# ESW3120 register map
Vendor: Shanghai Eastsoft Microelectronics Co.,Ltd.; Series: ARMCM3; File version: 1.2
CPU: CM3 r2p1, little endian, MPU, no FPU, 4 interrupt priority bits
Registers are 32-bit, read-write, reset 0x0 unless marked. A register's access mark holds for its fields unless they carry their own. Offsets are from the block's base; [hi:lo] are bit positions; {n}, {i} and the like mark numbered series.

## AFE
Base 0x400E0400
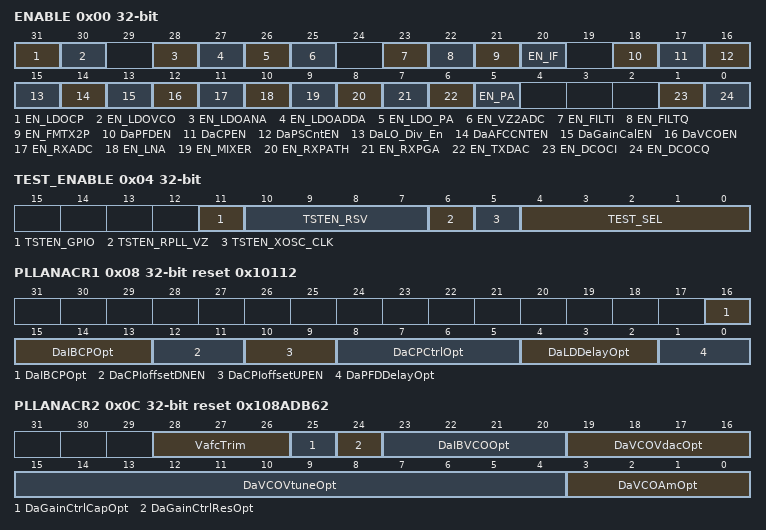
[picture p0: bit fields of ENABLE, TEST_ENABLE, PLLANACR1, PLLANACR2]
0x00 ENABLE
  [31] EN_LDOCP, [30] EN_LDOVCO, [28] EN_LDOANA, [27] EN_LDOADDA, [26] EN_LDO_PA, [25] EN_VZ2ADC, [23] EN_FILTI, [22] EN_FILTQ, [21] EN_FMTX2P, [20] EN_IF, [18] DaPFDEN, [17] DaCPEN, [16] DaPSCntEN, [15] DaLO_Div_En, [14] DaAFCCNTEN, [13] DaGainCalEN, [12] DaVCOEN, [11] EN_RXADC, [10] EN_LNA, [9] EN_MIXER, [8] EN_RXPATH, [7] EN_RXPGA, [6] EN_TXDAC, [5] EN_PA, [1] EN_DCOCI, [0] EN_DCOCQ
0x04 TEST_ENABLE
  [11] TSTEN_GPIO, [10:7] TSTEN_RSV, [6] TSTEN_RPLL_VZ, [5] TSTEN_XOSC_CLK, [4:0] TEST_SEL
0x08 PLLANACR1 reset 0x10112
  [16:13] DaIBCPOpt, [12:11] DaCPIoffsetDNEN, [10:9] DaCPIoffsetUPEN, [8:5] DaCPCtrlOpt, [4:2] DaLDDelayOpt, [1:0] DaPFDDelayOpt
0x0C PLLANACR2 reset 0x108ADB62
  [28:26] VafcTrim, [25] DaGainCtrlCapOpt, [24] DaGainCtrlResOpt, [23:20] DaIBVCOOpt, [19:16] DaVCOVdacOpt, [15:4] DaVCOVtuneOpt, [3:0] DaVCOAmOpt
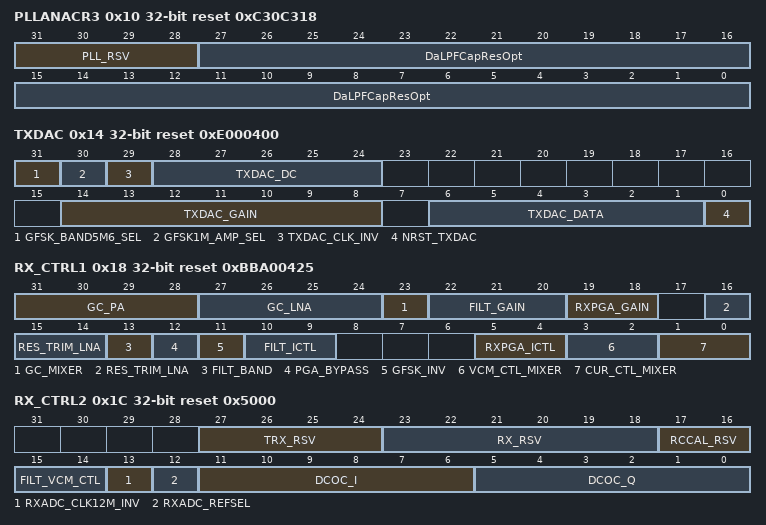
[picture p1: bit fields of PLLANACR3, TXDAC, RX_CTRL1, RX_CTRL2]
0x10 PLLANACR3 reset 0xC30C318
  [31:28] PLL_RSV, [27:0] DaLPFCapResOpt
0x14 TXDAC reset 0xE000400
  [31] GFSK_BAND5M6_SEL, [30] GFSK1M_AMP_SEL, [29] TXDAC_CLK_INV, [28:24] TXDAC_DC, [14:8] TXDAC_GAIN, [6:1] TXDAC_DATA, [0] NRST_TXDAC
0x18 RX_CTRL1 reset 0xBBA00425
  [31:28] GC_PA, [27:24] GC_LNA, [23] GC_MIXER, [22:20] FILT_GAIN, [19:18] RXPGA_GAIN, [16:14] RES_TRIM_LNA, [13] FILT_BAND, [12] PGA_BYPASS, [11] GFSK_INV, [10:9] FILT_ICTL, [5:4] RXPGA_ICTL, [3:2] VCM_CTL_MIXER, [1:0] CUR_CTL_MIXER
0x1C RX_CTRL2 reset 0x5000
  [27:24] TRX_RSV, [23:18] RX_RSV, [17:16] RCCAL_RSV, [15:14] FILT_VCM_CTL, [13] RXADC_CLK12M_INV, [12] RXADC_REFSEL, [11:6] DCOC_I, [5:0] DCOC_Q
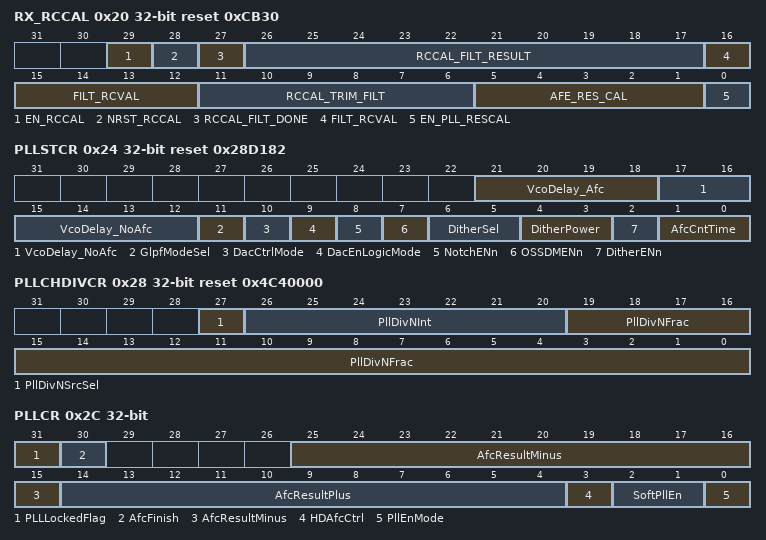
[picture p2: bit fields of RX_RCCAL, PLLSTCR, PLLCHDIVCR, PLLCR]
0x20 RX_RCCAL reset 0xCB30
  [29] EN_RCCAL, [28] NRST_RCCAL, [27] RCCAL_FILT_DONE read, [26:17] RCCAL_FILT_RESULT read, [16:12] FILT_RCVAL, [11:6] RCCAL_TRIM_FILT, [5:1] AFE_RES_CAL, [0] EN_PLL_RESCAL
0x24 PLLSTCR reset 0x28D182
  [21:18] VcoDelay_Afc, [17:12] VcoDelay_NoAfc, [11] GlpfModeSel, [10] DacCtrlMode, [9] DacEnLogicMode, [8] NotchENn, [7] OSSDMENn, [6:5] DitherSel, [4:3] DitherPower, [2] DitherENn, [1:0] AfcCntTime
0x28 PLLCHDIVCR reset 0x4C40000
  [27] PllDivNSrcSel, [26:20] PllDivNInt, [19:0] PllDivNFrac
0x2C PLLCR
  [31] PLLLockedFlag read, [30] AfcFinish read, [25:15] AfcResultMinus, [14:4] AfcResultPlus, [3] HDAfcCtrl, [2:1] SoftPllEn, [0] PllEnMode
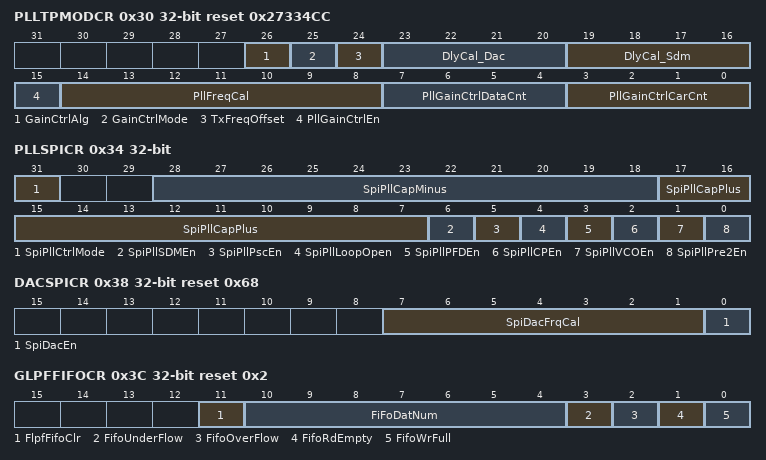
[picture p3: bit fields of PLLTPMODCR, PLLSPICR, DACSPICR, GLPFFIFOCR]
0x30 PLLTPMODCR reset 0x27334CC
  [26] GainCtrlAlg, [25] GainCtrlMode, [24] TxFreqOffset, [23:20] DlyCal_Dac, [19:16] DlyCal_Sdm, [15] PllGainCtrlEn, [14:8] PllFreqCal read, [7:4] PllGainCtrlDataCnt, [3:0] PllGainCtrlCarCnt
0x34 PLLSPICR
  [31] SpiPllCtrlMode, [28:18] SpiPllCapMinus, [17:7] SpiPllCapPlus, [6] SpiPllSDMEn, [5] SpiPllPscEn, [4] SpiPllLoopOpen, [3] SpiPllPFDEn, [2] SpiPllCPEn, [1] SpiPllVCOEn, [0] SpiPllPre2En
0x38 DACSPICR reset 0x68
  [7:1] SpiDacFrqCal, [0] SpiDacEn
0x3C GLPFFIFOCR read reset 0x2
  [11] FlpfFifoClr rw, [10:4] FiFoDatNum, [3] FifoUnderFlow, [2] FifoOverFlow, [1] FifoRdEmpty, [0] FifoWrFull
0x40 CTRL_MODE0
  [31:0] afe_ctrl_mode0
0x44 CTRL_MODE1
  [15:0] afe_ctrl_mode1
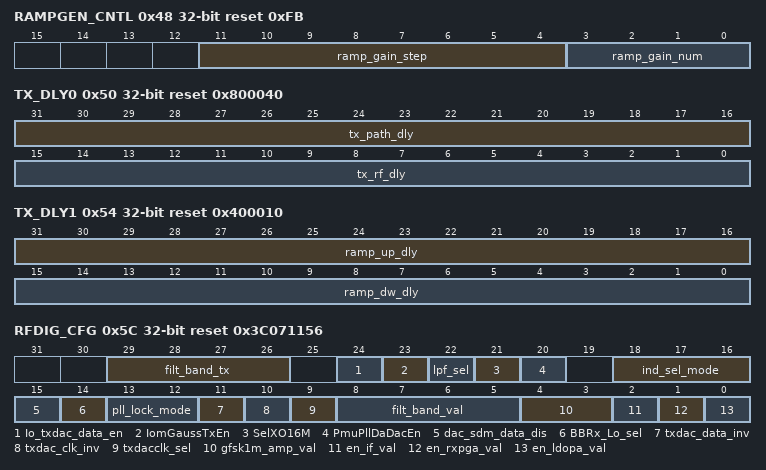
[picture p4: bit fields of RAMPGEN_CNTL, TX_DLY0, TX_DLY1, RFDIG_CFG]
0x48 RAMPGEN_CNTL reset 0xFB
  [11:4] ramp_gain_step, [3:0] ramp_gain_num
0x4C RPLL_DLY reset 0x500
  [15:0] rpll_dly
0x50 TX_DLY0 reset 0x800040
  [31:16] tx_path_dly, [15:0] tx_rf_dly
0x54 TX_DLY1 reset 0x400010
  [31:16] ramp_up_dly, [15:0] ramp_dw_dly
0x58 RX_DLY0 reset 0x40
  [15:0] rx_ana_dly
0x5C RFDIG_CFG reset 0x3C071156
  [29:26] filt_band_tx, [24] Io_txdac_data_en, [23] IomGaussTxEn, [22] lpf_sel, [21] SelXO16M, [20] PmuPllDaDacEn, [18:16] ind_sel_mode, [15] dac_sdm_data_dis, [14] BBRx_Lo_sel, [13:12] pll_lock_mode, [11] txdac_data_inv, [10] txdac_clk_inv, [9] txdacclk_sel, [8:5] filt_band_val, [4:3] gfsk1m_amp_val, [2] en_if_val, [1] en_rxpga_val, [0] en_ldopa_val
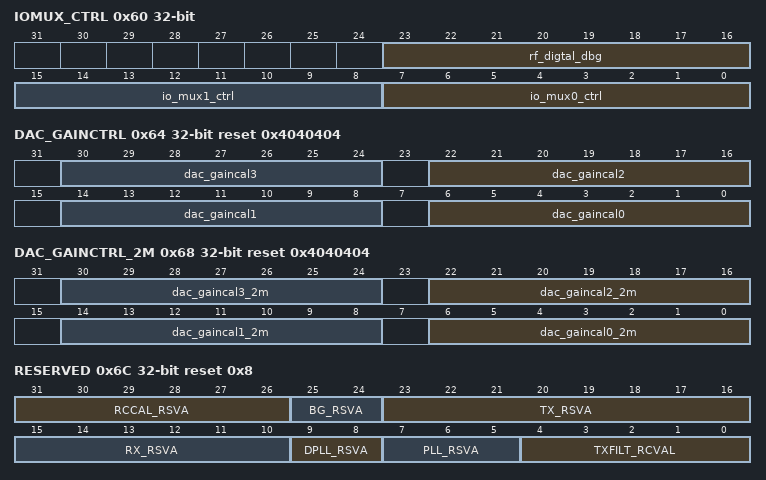
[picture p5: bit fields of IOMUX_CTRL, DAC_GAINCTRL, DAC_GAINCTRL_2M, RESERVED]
0x60 IOMUX_CTRL
  [23:16] rf_digtal_dbg read, [15:8] io_mux1_ctrl, [7:0] io_mux0_ctrl
0x64 DAC_GAINCTRL reset 0x4040404
  [8n+6:8n] dac_gaincal{n} (n=0..3)
0x68 DAC_GAINCTRL_2M reset 0x4040404
  [8n+6:8n] dac_gaincal{n}_2m (n=0..3)
0x6C RESERVED reset 0x8
  [31:26] RCCAL_RSVA, [25:24] BG_RSVA, [23:16] TX_RSVA, [15:10] RX_RSVA, [9:8] DPLL_RSVA, [7:5] PLL_RSVA, [4:0] TXFILT_RCVAL
